# STM32L151xBA register map
File version: 1.0
Registers are 32-bit, read-write, reset 0x0 unless marked. A register's access mark holds for its fields unless they carry their own. Offsets are from the block's base; [hi:lo] are bit positions.

## TIM10 — TIM
Base 0x40010C00
Same registers: TIM11 0x40011000
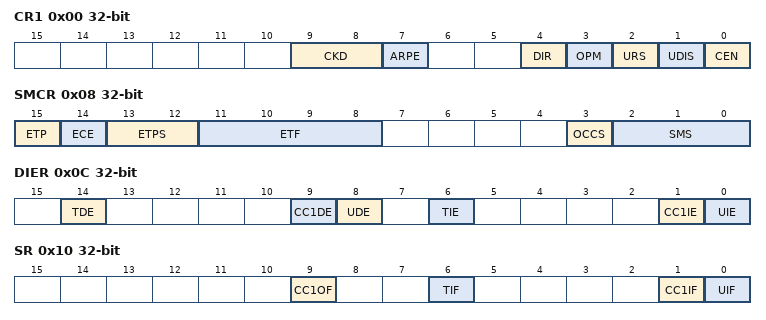
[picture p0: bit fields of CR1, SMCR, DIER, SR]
0x00 CR1 — TIM control register 1
  [9:8] CKD — CKD[1:0] bits (clock division)
    0=DIV1 (tDTS=tCK_INT); 1=DIV2 (tDTS=2*tCK_INT); 2=DIV4 (tDTS=4*tCK_INT)
  [7] ARPE — Auto-reload preload enable
  [4] DIR — Direction
    0=UP (Timer counter counts up); 1=DOWN (Timer counter counts down)
  [3] OPM — One pulse mode
    1=SINGLE (Counter stops counting at the next update event); 0=REPETITIVE (Counter is not stopped at update event)
  [2] URS — Update request source
    0=REGULAR (Counter overflow/underflow, Setting the UG bit or Update generation through the slave mode controller generates an update request); 1=COUNTER (Only counter overflow/underflow generates an update request)
  [1] UDIS — Update disable
  [0] CEN — Counter enable
0x04 CR2 — TIM control register 2
  [3] CCDS — Capture/Compare DMA Selection
    0=CC (CCx DMA request sent when CCx event occurs); 1=UPDATE (CCx DMA requests sent when update event occurs)
0x08 SMCR — TIM slave Mode Control register
  [15] ETP — External trigger polarity
  [14] ECE — External clock enable
  [13:12] ETPS — ETPS[1:0] bits (External trigger prescaler)
  [11:8] ETF — ETF[3:0] bits (External trigger filter)
  [3] OCCS — OCREF clear selection
    0=OCREF_CLR (OCREF_CLR_INT is connected to the OCREF_CLR input); 1=ETR (OCREF_CLR_INT is connected to ETRF)
  [2:0] SMS — SMS[2:0] bits (Slave mode selection)
    1=X2_TI1 (Quadrature encoder mode 1, x2 mode - Counter counts up/down on TI1FP1 edge depending on TI2FP2 level); 2=X2_TI2 (Quadrature encoder mode 2, x2 mode - Counter counts up/down on TI2FP2 edge depending on TI1FP1 level); 3=X4_TI12 (Quadrature encoder mode 3, x4 mode - Counter counts up/down on both TI1FP1 and TI2FP2 edges depending on the level of the other input); 0=DISABLED (Slave mode disabled); 4=RESET (Reset Mode - Rising edge of the selected trigger input (TRGI) reinitializes the counter); 5=GATED (Gated Mode - The counter clock is enabled when the trigger input (TRGI) is high); 6=TRIGGER (Trigger Mode - The counter starts at a rising edge of the trigger TRGI)
0x0C DIER — TIM DMA/interrupt enable register
  [14] TDE — Trigger DMA request enable
  [9] CC1DE — Capture/Compare 1 DMA request enable
  [8] UDE — Update DMA request enable
  [6] TIE — Trigger interrupt enable
  [1] CC1IE — Capture/Compare 1 interrupt enable
  [0] UIE — Update interrupt enable
0x10 SR — TIM status register
  [9] CC1OF — Capture/Compare 1 Overcapture Flag
  [6] TIF — Trigger interrupt Flag
  [1] CC1IF — Capture/Compare 1 interrupt Flag
  [0] UIF — Update interrupt Flag
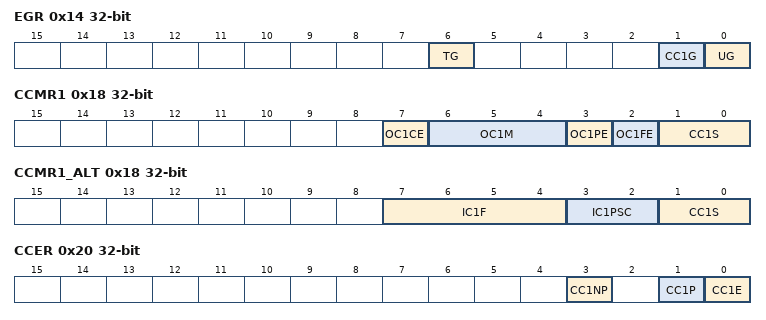
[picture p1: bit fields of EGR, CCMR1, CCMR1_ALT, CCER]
0x14 EGR — TIM event generation register
  [6] TG — Trigger Generation
  [1] CC1G — Capture/Compare 1 Generation
  [0] UG — Update Generation
0x18 CCMR1 — TIM capture/compare mode register 1
  [7] OC1CE — Output Compare 1Clear Enable
  [6:4] OC1M — OC1M[2:0] bits (Output Compare 1 Mode)
  [3] OC1PE — Output Compare 1 Preload enable
  [2] OC1FE — Output Compare 1 Fast enable
  [1:0] CC1S — CC1S[1:0] bits (Capture/Compare 1 Selection)
0x18 CCMR1_ALT (alternate view of CCMR1) — TIM capture/compare mode register 1
  [7:4] IC1F — IC1F[3:0] bits (Input Capture 1 Filter)
  [3:2] IC1PSC — IC1PSC[1:0] bits (Input Capture 1 Prescaler)
  [1:0] CC1S — CC1S[1:0] bits (Capture/Compare 1 Selection)
0x20 CCER — TIM capture/compare enable register
  [3] CC1NP — Capture/Compare 1 Complementary output Polarity
  [1] CC1P — Capture/Compare 1 output Polarity
  [0] CC1E — Capture/Compare 1 output enable
0x24 CNT — TIM counter register
  [15:0] CNT — Counter Value
0x28 PSC — TIM prescaler register
  [15:0] PSC — Prescaler Value
0x2C ARR — TIM auto-reload register
  [15:0] ARR — actual auto-reload Value
0x34 CCR1 — TIM capture/compare register 1
  [15:0] CCR1 — Capture/Compare 1 Value
0x4C DMAR — TIM DMA address for full transfer
  [15:0] DMAB — DMA register for burst accesses
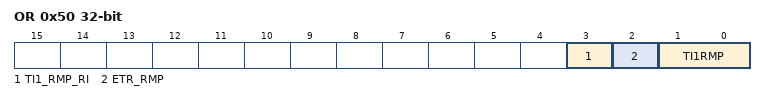
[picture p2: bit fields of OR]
0x50 OR — TIM option register
  [3] TI1_RMP_RI — TI1_RMP_RI bit (TIM10/11 Input 1 remap for Routing interface)
  [2] ETR_RMP — ETR_RMP bit (TIM10/11 ETR remap)
  [1:0] TI1RMP — TI1_RMP[1:0] bits (TIM Input 1 remap)
